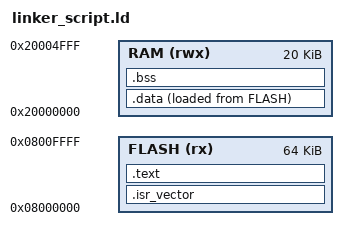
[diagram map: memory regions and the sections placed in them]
MEMORY
{
	FLASH(rx) : ORIGIN = 0x08000000, LENGTH = 64k
	RAM (rwx) : ORIGIN = 0x20000000, LENGTH = 20k
}

/*Точка входа*/

ENTRY(Reset_handler)

SECTIONS
{
	/*Секция Векторов Прерываний (должна лежать в самом начале FLASH)*/
	.isr_vector :
	{
		. = ALIGN(4);
		KEEP(*(.isr_vector))/*Запрещаем линкеру удалять эту таблицу*/
		. = ALIGN(4);
	} > FLASH

	/*Секция кода программы*/	
	.text :
	{
		. = ALIGN(4);
		*(.text)/*Весь мой код*/	
		*(.rodata)/*КОНСТАНТЫ*/
		. = ALIGN(4);
	} > FLASH

	/*Переменные  с начальным значением (инициализированные)*/
	.data :
	{
		. = ALIGN(4);
		_sdata = .; /*Маркер  начала секции .data в RAM*/
		*(.data)
		. = ALIGN(4);
		_edata = .; /*Маркер конца секции .data в RAM*/	
	} > RAM AT> FLASH /*Храняться во ФЛЕШЕ но работают В РАМ !!*/

	.bss : /*Секция неинициализированых переменных (должна быть в 0)*/
	{
		. = ALIGN(4);
		_sbss = .;	/*Старт секции неинициализированых переменных*/	
		*(.bss)
		. = ALIGN(4);
		_ebss = .; /*Маркер Конца секции неинициализированых переменных*/
	} > RAM	
}

